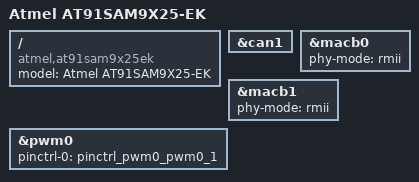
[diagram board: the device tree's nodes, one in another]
/dts-v1/;
#include "at91sam9x25.dtsi"
#include "at91sam9x5ek.dtsi"
/ {
	model = "Atmel AT91SAM9X25-EK";
	compatible = "atmel,at91sam9x25ek", "atmel,at91sam9x5ek", "atmel,at91sam9x5", "atmel,at91sam9";
};
&can1 {
	status = "okay";
};
&macb0 {
	phy-mode = "rmii";
	status = "okay";
};
&macb1 {
	phy-mode = "rmii";
	status = "okay";
};
&pwm0 {
	pinctrl-names = "default";
	pinctrl-0 = <&pinctrl_pwm0_pwm0_1>;
	status = "okay";
};
